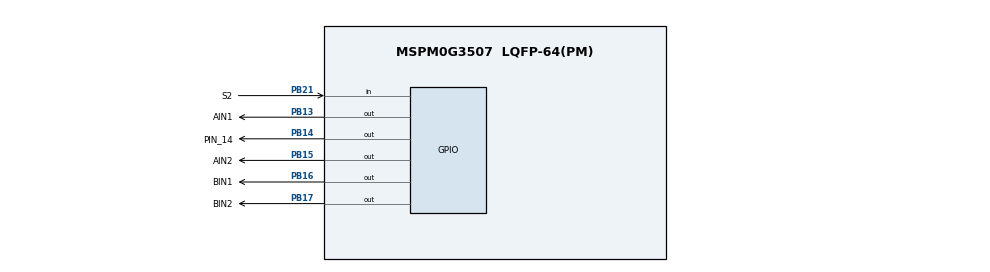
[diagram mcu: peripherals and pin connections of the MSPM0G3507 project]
/**
 * These arguments were used when this file was generated. They will be automatically applied on subsequent loads
 * via the GUI or CLI. Run CLI with '--help' for additional information on how to override these arguments.
 * @cliArgs --device "MSPM0G350X" --part "Default" --package "LQFP-64(PM)" --product "mspm0_sdk@2.05.00.05"
 * @v2CliArgs --device "MSPM0G3507" --package "LQFP-64(PM)" --product "mspm0_sdk@2.05.00.05"
 * @versions {"tool":"1.23.1+4034"}
 */
scripting.excludeFromBuild("Event.dot");

/**
 * Import the modules used in this configuration.
 */
const DMA           = scripting.addModule("/ti/driverlib/DMA");
const GPIO          = scripting.addModule("/ti/driverlib/GPIO", {}, false);
const GPIO1         = GPIO.addInstance();
const GPIO2         = GPIO.addInstance();
const GPIO3         = GPIO.addInstance();
const GPIO4         = GPIO.addInstance();
const I2C           = scripting.addModule("/ti/driverlib/I2C", {}, false);
const I2C1          = I2C.addInstance();
const PWM           = scripting.addModule("/ti/driverlib/PWM", {}, false);
const PWM1          = PWM.addInstance();
const QEI           = scripting.addModule("/ti/driverlib/QEI", {}, false);
const QEI1          = QEI.addInstance();
const SPI           = scripting.addModule("/ti/driverlib/SPI", {}, false);
const SPI1          = SPI.addInstance();
const SYSCTL        = scripting.addModule("/ti/driverlib/SYSCTL");
const TIMER         = scripting.addModule("/ti/driverlib/TIMER", {}, false);
const TIMER1        = TIMER.addInstance();
const UART          = scripting.addModule("/ti/driverlib/UART", {}, false);
const UART1         = UART.addInstance();
const UART2         = UART.addInstance();
const UART3         = UART.addInstance();
const UART4         = UART.addInstance();
const ProjectConfig = scripting.addModule("/ti/project_config/ProjectConfig");

/**
 * Write custom configuration values to the imported modules.
 */
const Board = scripting.addModule("/ti/driverlib/Board", {}, false);

GPIO1.$name                         = "LED";
GPIO1.port                          = "PORTB";
GPIO1.associatedPins[0].$name       = "PIN_14";
GPIO1.associatedPins[0].pin.$assign = "PB14";

GPIO2.$name                         = "TB6612";
GPIO2.associatedPins.create(4);
GPIO2.associatedPins[0].$name       = "AIN1";
GPIO2.associatedPins[0].pin.$assign = "PB13";
GPIO2.associatedPins[1].$name       = "AIN2";
GPIO2.associatedPins[1].pin.$assign = "PB15";
GPIO2.associatedPins[2].$name       = "BIN1";
GPIO2.associatedPins[2].pin.$assign = "PB16";
GPIO2.associatedPins[3].$name       = "BIN2";
GPIO2.associatedPins[3].pin.$assign = "PB17";

GPIO3.$name                         = "Butter";
GPIO3.port                          = "PORTB";
GPIO3.portSegment                   = "Upper";
GPIO3.associatedPins[0].$name       = "S2";
GPIO3.associatedPins[0].direction   = "INPUT";
GPIO3.associatedPins[0].pin.$assign = "PB21";

GPIO4.$name                   = "OLED_SPI";
GPIO4.associatedPins.create(5);
GPIO4.associatedPins[0].$name = "CS3_RES";
GPIO4.associatedPins[1].$name = "CS";
GPIO4.associatedPins[2].$name = "CS2_DC";
GPIO4.associatedPins[3].$name = "SCK_D0";
GPIO4.associatedPins[4].$name = "MOSI_D1";

I2C1.$name                             = "I2C_OLED";
I2C1.basicEnableController             = true;
I2C1.basicControllerStandardBusSpeed   = "Fast";
I2C1.sdaPinConfig.hideOutputInversion  = scripting.forceWrite(false);
I2C1.sdaPinConfig.onlyInternalResistor = scripting.forceWrite(false);
I2C1.sdaPinConfig.passedPeripheralType = scripting.forceWrite("Digital");
I2C1.sdaPinConfig.$name                = "ti_driverlib_gpio_GPIOPinGeneric21";
I2C1.sclPinConfig.hideOutputInversion  = scripting.forceWrite(false);
I2C1.sclPinConfig.onlyInternalResistor = scripting.forceWrite(false);
I2C1.sclPinConfig.passedPeripheralType = scripting.forceWrite("Digital");
I2C1.sclPinConfig.$name                = "ti_driverlib_gpio_GPIOPinGeneric22";

PWM1.$name                              = "Motor";
PWM1.timerCount                         = 8000;
PWM1.timerStartTimer                    = true;
PWM1.PWM_CHANNEL_0.$name                = "ti_driverlib_pwm_PWMTimerCC0";
PWM1.PWM_CHANNEL_1.$name                = "ti_driverlib_pwm_PWMTimerCC1";
PWM1.ccp0PinConfig.direction            = scripting.forceWrite("OUTPUT");
PWM1.ccp0PinConfig.hideOutputInversion  = scripting.forceWrite(false);
PWM1.ccp0PinConfig.onlyInternalResistor = scripting.forceWrite(false);
PWM1.ccp0PinConfig.passedPeripheralType = scripting.forceWrite("Digital");
PWM1.ccp0PinConfig.$name                = "ti_driverlib_gpio_GPIOPinGeneric6";
PWM1.ccp1PinConfig.direction            = scripting.forceWrite("OUTPUT");
PWM1.ccp1PinConfig.hideOutputInversion  = scripting.forceWrite(false);
PWM1.ccp1PinConfig.onlyInternalResistor = scripting.forceWrite(false);
PWM1.ccp1PinConfig.passedPeripheralType = scripting.forceWrite("Digital");
PWM1.ccp1PinConfig.$name                = "ti_driverlib_gpio_GPIOPinGeneric7";

QEI1.$name               = "QEI_0";
QEI1.enableIndexInput    = true;
QEI1.ccp0PinConfig.$name = "ti_driverlib_gpio_GPIOPinGeneric2";
QEI1.ccp1PinConfig.$name = "ti_driverlib_gpio_GPIOPinGeneric3";
QEI1.idxPinConfig.$name  = "ti_driverlib_gpio_GPIOPinGeneric4";

SPI1.targetBitRate                      = 16000000;
SPI1.enableDMAEvent2                    = false;
SPI1.$name                              = "SPI_MCU";
SPI1.enabledDMAEvent1Triggers           = "DL_SPI_DMA_INTERRUPT_RX";
SPI1.sclkPinConfig.direction            = scripting.forceWrite("OUTPUT");
SPI1.sclkPinConfig.onlyInternalResistor = scripting.forceWrite(false);
SPI1.sclkPinConfig.passedPeripheralType = scripting.forceWrite("Digital");
SPI1.sclkPinConfig.$name                = "ti_driverlib_gpio_GPIOPinGeneric13";
SPI1.mosiPinConfig.direction            = scripting.forceWrite("OUTPUT");
SPI1.mosiPinConfig.hideOutputInversion  = scripting.forceWrite(false);
SPI1.mosiPinConfig.onlyInternalResistor = scripting.forceWrite(false);
SPI1.mosiPinConfig.passedPeripheralType = scripting.forceWrite("Digital");
SPI1.mosiPinConfig.$name                = "ti_driverlib_gpio_GPIOPinGeneric14";
SPI1.misoPinConfig.onlyInternalResistor = scripting.forceWrite(false);
SPI1.misoPinConfig.passedPeripheralType = scripting.forceWrite("Digital");
SPI1.misoPinConfig.$name                = "ti_driverlib_gpio_GPIOPinGeneric15";
SPI1.cs0PinConfig.direction             = scripting.forceWrite("OUTPUT");
SPI1.cs0PinConfig.hideOutputInversion   = scripting.forceWrite(false);
SPI1.cs0PinConfig.onlyInternalResistor  = scripting.forceWrite(false);
SPI1.cs0PinConfig.passedPeripheralType  = scripting.forceWrite("Digital");
SPI1.cs0PinConfig.$name                 = "ti_driverlib_gpio_GPIOPinGeneric16";
SPI1.DMA_CHANNEL_EVENT1.$name           = "DMA_SPI";

SYSCTL.forceDefaultClkConfig = true;
SYSCTL.clockTreeEn           = true;

TIMER1.$name             = "TIMER_0";
TIMER1.timerMode         = "PERIODIC";
TIMER1.interrupts        = ["ZERO"];
TIMER1.interruptPriority = "1";
TIMER1.timerPeriod       = "5 ms";
TIMER1.timerClkDiv       = 4;
TIMER1.timerStartTimer   = true;

UART1.$name                            = "UART_1";
UART1.targetBaudRate                   = 115200;
UART1.txPinConfig.direction            = scripting.forceWrite("OUTPUT");
UART1.txPinConfig.hideOutputInversion  = scripting.forceWrite(false);
UART1.txPinConfig.onlyInternalResistor = scripting.forceWrite(false);
UART1.txPinConfig.passedPeripheralType = scripting.forceWrite("Digital");
UART1.txPinConfig.$name                = "ti_driverlib_gpio_GPIOPinGeneric8";
UART1.rxPinConfig.hideOutputInversion  = scripting.forceWrite(false);
UART1.rxPinConfig.onlyInternalResistor = scripting.forceWrite(false);
UART1.rxPinConfig.passedPeripheralType = scripting.forceWrite("Digital");
UART1.rxPinConfig.$name                = "ti_driverlib_gpio_GPIOPinGeneric9";

UART2.$name                            = "UART_0";
UART2.txPinConfig.direction            = scripting.forceWrite("OUTPUT");
UART2.txPinConfig.hideOutputInversion  = scripting.forceWrite(false);
UART2.txPinConfig.onlyInternalResistor = scripting.forceWrite(false);
UART2.txPinConfig.passedPeripheralType = scripting.forceWrite("Digital");
UART2.txPinConfig.$name                = "ti_driverlib_gpio_GPIOPinGeneric0";
UART2.rxPinConfig.hideOutputInversion  = scripting.forceWrite(false);
UART2.rxPinConfig.onlyInternalResistor = scripting.forceWrite(false);
UART2.rxPinConfig.passedPeripheralType = scripting.forceWrite("Digital");
UART2.rxPinConfig.$name                = "ti_driverlib_gpio_GPIOPinGeneric1";

UART3.$name             = "UART_2";
UART3.txPinConfig.$name = "ti_driverlib_gpio_GPIOPinGeneric5";
UART3.rxPinConfig.$name = "ti_driverlib_gpio_GPIOPinGeneric10";

UART4.$name             = "UART_3";
UART4.targetBaudRate    = 115200;
UART4.txPinConfig.$name = "ti_driverlib_gpio_GPIOPinGeneric11";
UART4.rxPinConfig.$name = "ti_driverlib_gpio_GPIOPinGeneric12";

ProjectConfig.genStartup = false;
ProjectConfig.genLinker  = false;
ProjectConfig.genOpts    = false;
ProjectConfig.genLibs    = false;

/**
 * Pinmux solution for unlocked pins/peripherals. This ensures that minor changes to the automatic solver in a future
 * version of the tool will not impact the pinmux you originally saw.  These lines can be completely deleted in order to
 * re-solve from scratch.
 */
Board.peripheral.$suggestSolution                   = "DEBUGSS";
Board.peripheral.swclkPin.$suggestSolution          = "PA20";
Board.peripheral.swdioPin.$suggestSolution          = "PA19";
GPIO4.associatedPins[0].pin.$suggestSolution        = "PA12";
GPIO4.associatedPins[1].pin.$suggestSolution        = "PB18";
GPIO4.associatedPins[2].pin.$suggestSolution        = "PB19";
GPIO4.associatedPins[3].pin.$suggestSolution        = "PB20";
GPIO4.associatedPins[4].pin.$suggestSolution        = "PB22";
I2C1.peripheral.$suggestSolution                    = "I2C1";
I2C1.peripheral.sdaPin.$suggestSolution             = "PA3";
I2C1.peripheral.sclPin.$suggestSolution             = "PA29";
PWM1.peripheral.$suggestSolution                    = "TIMA1";
PWM1.peripheral.ccp0Pin.$suggestSolution            = "PA28";
PWM1.peripheral.ccp1Pin.$suggestSolution            = "PA16";
QEI1.peripheral.$suggestSolution                    = "TIMG8";
QEI1.peripheral.ccp0Pin.$suggestSolution            = "PA23";
QEI1.peripheral.ccp1Pin.$suggestSolution            = "PA27";
QEI1.peripheral.idxPin.$suggestSolution             = "PA15";
SPI1.peripheral.$suggestSolution                    = "SPI0";
SPI1.peripheral.sclkPin.$suggestSolution            = "PA11";
SPI1.peripheral.mosiPin.$suggestSolution            = "PA5";
SPI1.peripheral.misoPin.$suggestSolution            = "PA10";
SPI1.peripheral.cs0Pin.$suggestSolution             = "PA2";
SPI1.DMA_CHANNEL_EVENT1.peripheral.$suggestSolution = "DMA_CH1";
TIMER1.peripheral.$suggestSolution                  = "TIMA0";
UART1.peripheral.$suggestSolution                   = "UART3";
UART1.peripheral.rxPin.$suggestSolution             = "PA13";
UART1.peripheral.txPin.$suggestSolution             = "PA14";
UART2.peripheral.$suggestSolution                   = "UART2";
UART2.peripheral.rxPin.$suggestSolution             = "PA22";
UART2.peripheral.txPin.$suggestSolution             = "PA21";
UART3.peripheral.$suggestSolution                   = "UART1";
UART3.peripheral.rxPin.$suggestSolution             = "PA18";
UART3.peripheral.txPin.$suggestSolution             = "PA17";
UART4.peripheral.$suggestSolution                   = "UART0";
UART4.peripheral.rxPin.$suggestSolution             = "PA1";
UART4.peripheral.txPin.$suggestSolution             = "PA0";
